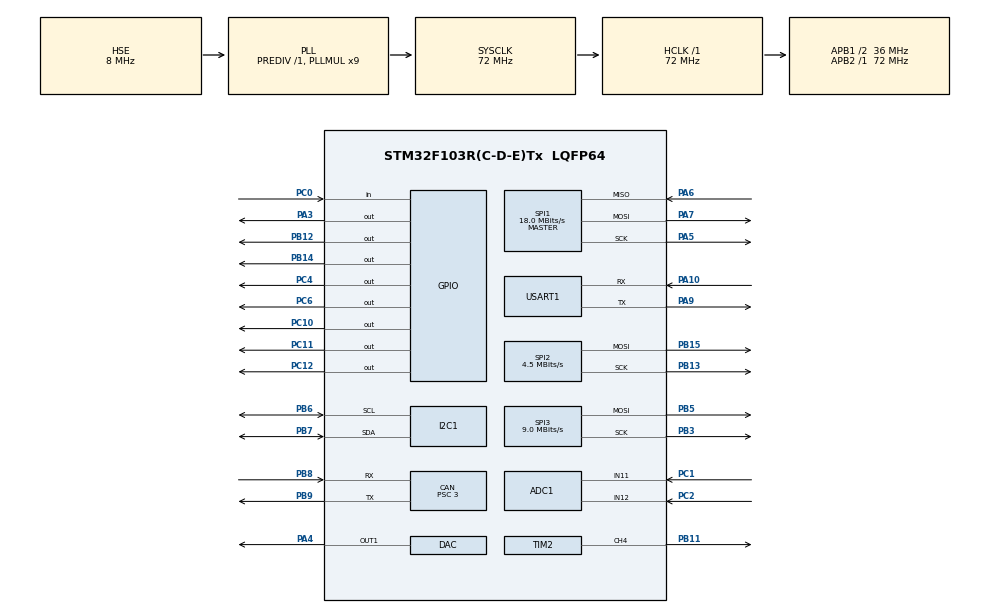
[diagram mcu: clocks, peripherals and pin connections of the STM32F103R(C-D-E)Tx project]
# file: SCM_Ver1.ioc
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ADC1.Channel-0\#ChannelRegularConversion=ADC_CHANNEL_11
ADC1.NbrOfConversionFlag=1
ADC1.master=1
CAN.ABOM=ENABLE
CAN.BS1=CAN_BS1_5TQ
CAN.BS2=CAN_BS2_6TQ
CAN.CalculateTimeBit=1000
CAN.CalculateTimeQuantum=83.33333333333334
CAN.Mode=CAN_MODE_NORMAL
CAN.Prescaler=3
Dma.Request0=USART1_TX
Dma.Request1=USART1_RX
Dma.Request2=SPI3_TX
Dma.SPI3_TX.2.Direction=DMA_MEMORY_TO_PERIPH
Dma.SPI3_TX.2.Instance=DMA2_Channel2
Dma.SPI3_TX.2.MemDataAlignment=DMA_MDATAALIGN_BYTE
Dma.SPI3_TX.2.MemInc=DMA_MINC_ENABLE
Dma.SPI3_TX.2.Mode=DMA_NORMAL
Dma.SPI3_TX.2.PeriphDataAlignment=DMA_PDATAALIGN_BYTE
Dma.SPI3_TX.2.PeriphInc=DMA_PINC_DISABLE
Dma.SPI3_TX.2.Priority=DMA_PRIORITY_LOW
Dma.USART1_RX.1.Direction=DMA_PERIPH_TO_MEMORY
Dma.USART1_RX.1.Instance=DMA1_Channel5
Dma.USART1_RX.1.MemDataAlignment=DMA_MDATAALIGN_BYTE
Dma.USART1_RX.1.MemInc=DMA_MINC_ENABLE
Dma.USART1_RX.1.Mode=DMA_CIRCULAR
Dma.USART1_RX.1.PeriphDataAlignment=DMA_PDATAALIGN_BYTE
Dma.USART1_RX.1.PeriphInc=DMA_PINC_DISABLE
Dma.USART1_RX.1.Priority=DMA_PRIORITY_HIGH
Dma.USART1_TX.0.Direction=DMA_MEMORY_TO_PERIPH
Dma.USART1_TX.0.Instance=DMA1_Channel4
Dma.USART1_TX.0.MemDataAlignment=DMA_MDATAALIGN_BYTE
Dma.USART1_TX.0.MemInc=DMA_MINC_ENABLE
Dma.USART1_TX.0.Mode=DMA_NORMAL
Dma.USART1_TX.0.PeriphDataAlignment=DMA_PDATAALIGN_BYTE
Dma.USART1_TX.0.PeriphInc=DMA_PINC_DISABLE
Dma.USART1_TX.0.Priority=DMA_PRIORITY_HIGH
I2C1.I2C_Mode=I2C_Standard
Mcu.Family=STM32F1
Mcu.Name=STM32F103R(C-D-E)Tx
Mcu.Package=LQFP64
NVIC.DMA1_Channel4_IRQn=true\:0\:0\:false\:false\:true\:false\:true
NVIC.DMA1_Channel5_IRQn=true\:0\:0\:false\:false\:true\:false\:true
NVIC.DMA2_Channel2_IRQn=true\:0\:0\:false\:false\:true\:false\:true
NVIC.PriorityGroup=NVIC_PRIORITYGROUP_4
NVIC.TIM1_UP_IRQn=true\:0\:0\:false\:true\:true\:2\:true\:true
NVIC.USART1_IRQn=true\:1\:0\:true\:true\:true\:1\:true\:true
NVIC.USB_LP_CAN1_RX0_IRQn=true\:1\:0\:true\:false\:true\:true\:true
PA10.Mode=Asynchronous
PA10.Signal=USART1_RX
PA13.Mode=Serial_Wire
PA13.Signal=SYS_JTMS-SWDIO
PA14.Mode=Serial_Wire
PA14.Signal=SYS_JTCK-SWCLK
PA3.Signal=GPIO_Output
PA4.Signal=COMP_DAC1_group
PA5.Mode=Full_Duplex_Master
PA5.Signal=SPI1_SCK
PA6.Mode=Full_Duplex_Master
PA6.Signal=SPI1_MISO
PA7.Mode=Full_Duplex_Master
PA7.Signal=SPI1_MOSI
PA9.Mode=Asynchronous
PA9.Signal=USART1_TX
PB11.Signal=S_TIM2_CH4
PB12.Signal=GPIO_Output
PB13.Mode=TX_Only_Simplex_Unidirect_Master
PB13.Signal=SPI2_SCK
PB14.Signal=GPIO_Output
PB15.Mode=TX_Only_Simplex_Unidirect_Master
PB15.Signal=SPI2_MOSI
PB3.Mode=TX_Only_Simplex_Unidirect_Master
PB3.Signal=SPI3_SCK
PB5.Mode=TX_Only_Simplex_Unidirect_Master
PB5.Signal=SPI3_MOSI
PB6.Mode=I2C
PB6.Signal=I2C1_SCL
PB7.Mode=I2C
PB7.Signal=I2C1_SDA
PB8.Mode=Master
PB8.Signal=CAN_RX
PB9.Mode=Master
PB9.Signal=CAN_TX
PC0.Signal=GPIO_Input
PC1.Signal=ADCx_IN11
PC10.Signal=GPIO_Output
PC11.Signal=GPIO_Output
PC12.Signal=GPIO_Output
PC2.Signal=ADCx_IN12
PC4.Signal=GPIO_Output
PC6.Signal=GPIO_Output
PD0-OSC_IN.Mode=HSE-External-Oscillator
PD0-OSC_IN.Signal=RCC_OSC_IN
PD1-OSC_OUT.Mode=HSE-External-Oscillator
PD1-OSC_OUT.Signal=RCC_OSC_OUT
ProjectManager.HeapSize=0x200
ProjectManager.StackSize=0x400
ProjectManager.TargetToolchain=STM32CubeIDE
RCC.ADCPresc=RCC_ADCPCLK2_DIV6
RCC.AHBFreq_Value=72000000
RCC.APB1CLKDivider=RCC_HCLK_DIV2
RCC.APB1Freq_Value=36000000
RCC.APB1TimFreq_Value=72000000
RCC.APB2Freq_Value=72000000
RCC.APB2TimFreq_Value=72000000
RCC.HCLKFreq_Value=72000000
RCC.PLLMUL=RCC_PLL_MUL9
RCC.PLLSourceVirtual=RCC_PLLSOURCE_HSE
RCC.SYSCLKFreq_VALUE=72000000
RCC.SYSCLKSource=RCC_SYSCLKSOURCE_PLLCLK
RCC.USBFreq_Value=48000000
RCC.USBPrescaler=RCC_USBCLKSOURCE_PLL_DIV1_5
SH.ADCx_IN11.0=ADC1_IN11,IN11
SH.ADCx_IN12.0=ADC1_IN12,IN12
SH.COMP_DAC1_group.0=DAC_OUT1,DAC_OUT1
SH.S_TIM2_CH4.0=TIM2_CH4,PWM Generation4 CH4
SPI1.BaudRatePrescaler=SPI_BAUDRATEPRESCALER_4
SPI1.CalculateBaudRate=18.0 MBits/s
SPI1.Direction=SPI_DIRECTION_2LINES
SPI1.Mode=SPI_MODE_MASTER
SPI1.VirtualType=VM_MASTER
SPI2.BaudRatePrescaler=SPI_BAUDRATEPRESCALER_8
SPI2.CalculateBaudRate=4.5 MBits/s
SPI2.Direction=SPI_DIRECTION_2LINES
SPI2.Mode=SPI_MODE_MASTER
SPI2.VirtualType=VM_MASTER
SPI3.BaudRatePrescaler=SPI_BAUDRATEPRESCALER_4
SPI3.CalculateBaudRate=9.0 MBits/s
SPI3.Direction=SPI_DIRECTION_2LINES
SPI3.Mode=SPI_MODE_MASTER
SPI3.VirtualType=VM_MASTER
TIM1.Period=999
TIM1.Prescaler=71
TIM2.AutoReloadPreload=TIM_AUTORELOAD_PRELOAD_DISABLE
TIM2.Channel-PWM\ Generation4\ CH4=TIM_CHANNEL_4
TIM2.Period=1000-1
TIM2.Prescaler=72-1
TIM2.Pulse-PWM\ Generation4\ CH4=500
USART1.VirtualMode=VM_ASYNC
VP_CRC_VS_CRC.Mode=CRC_Activate
VP_TIM1_VS_ClockSourceINT.Mode=Internal
board=custom

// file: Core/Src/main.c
/* USER CODE BEGIN Header */
/**
  ******************************************************************************
  * @file           : main.c
  * @brief          : Main program body
  ******************************************************************************
  * @attention
  *
  * <h2><center>&copy; Copyright (c) 2019 STMicroelectronics.
  * All rights reserved.</center></h2>
  *
  * This software component is licensed by ST under BSD 3-Clause license,
  * the "License"; You may not use this file except in compliance with the
  * License. You may obtain a copy of the License at:
  *                        opensource.org/licenses/BSD-3-Clause
  *
  ******************************************************************************
  */
/* USER CODE END Header */

#include "main.h"
#include "adc.h"
#include "can.h"
#include "crc.h"
#include "dac.h"
#include "dma.h"
#include "i2c.h"
#include "spi.h"
#include "tim.h"
#include "usart.h"
#include "gpio.h"

/* USER CODE BEGIN Includes */
#include "CRC.h"
#include "SCM.h"
#include "ina226.h"
#include "ssd1306.h"
#include "upper.h"
/* USER CODE END Includes */

void SystemClock_Config(void);
static void MX_NVIC_Init(void);

int main(void)
{

  /* MCU Configuration--------------------------------------------------------*/

  /* Reset of all peripherals, Initializes the Flash interface and the Systick. */
  HAL_Init();

  /* Configure the system clock */
  SystemClock_Config();

  /* Initialize all configured peripherals */
  MX_GPIO_Init();
  MX_DMA_Init();
  MX_ADC1_Init();
  MX_CAN_Init();
  MX_DAC_Init();
  MX_I2C1_Init();
  MX_SPI1_Init();
  MX_SPI2_Init();
  MX_SPI3_Init();
  MX_TIM2_Init();
  MX_USART1_UART_Init();
  MX_TIM1_Init();
  MX_CRC_Init();

  /* Initialize interrupts */
  MX_NVIC_Init();
  /* USER CODE BEGIN 2 */

	  HAL_TIM_PWM_Start(&htim2,TIM_CHANNEL_4); //Breath light
	  HAL_DAC_Start(&hdac,DAC_CHANNEL_1);
	  HAL_CAN_MspInit(&hcan);
	  //Enable UART IDLE interrupt and set DMA for Unfixed-length Data Receiving
	  SCM_Init();
	  Ina226_Init();
	  ssd1306_Init();
	  UART_InitForUpper(&huart1);
	  MPU9255_Init();
	  //Start Tim1 for control task interrupt
	  HAL_TIM_Base_Start_IT(&htim1);
  /* USER CODE END 2 */

  /* Infinite loop */
   while (1)
  {

  }
}

void SystemClock_Config(void)
{
  RCC_OscInitTypeDef RCC_OscInitStruct = {0};
  RCC_ClkInitTypeDef RCC_ClkInitStruct = {0};
  RCC_PeriphCLKInitTypeDef PeriphClkInit = {0};

  /** Initializes the CPU, AHB and APB busses clocks
  */
  RCC_OscInitStruct.OscillatorType = RCC_OSCILLATORTYPE_HSE;
  RCC_OscInitStruct.HSEState = RCC_HSE_ON;
  RCC_OscInitStruct.HSEPredivValue = RCC_HSE_PREDIV_DIV1;
  RCC_OscInitStruct.HSIState = RCC_HSI_ON;
  RCC_OscInitStruct.PLL.PLLState = RCC_PLL_ON;
  RCC_OscInitStruct.PLL.PLLSource = RCC_PLLSOURCE_HSE;
  RCC_OscInitStruct.PLL.PLLMUL = RCC_PLL_MUL9;
  if (HAL_RCC_OscConfig(&RCC_OscInitStruct) != HAL_OK)
  {
    Error_Handler();
  }
  /** Initializes the CPU, AHB and APB busses clocks
  */
  RCC_ClkInitStruct.ClockType = RCC_CLOCKTYPE_HCLK|RCC_CLOCKTYPE_SYSCLK
                              |RCC_CLOCKTYPE_PCLK1|RCC_CLOCKTYPE_PCLK2;
  RCC_ClkInitStruct.SYSCLKSource = RCC_SYSCLKSOURCE_PLLCLK;
  RCC_ClkInitStruct.AHBCLKDivider = RCC_SYSCLK_DIV1;
  RCC_ClkInitStruct.APB1CLKDivider = RCC_HCLK_DIV2;
  RCC_ClkInitStruct.APB2CLKDivider = RCC_HCLK_DIV1;

  if (HAL_RCC_ClockConfig(&RCC_ClkInitStruct, FLASH_LATENCY_2) != HAL_OK)
  {
    Error_Handler();
  }
  PeriphClkInit.PeriphClockSelection = RCC_PERIPHCLK_ADC;
  PeriphClkInit.AdcClockSelection = RCC_ADCPCLK2_DIV6;
  if (HAL_RCCEx_PeriphCLKConfig(&PeriphClkInit) != HAL_OK)
  {
    Error_Handler();
  }
}

/**
  * @brief NVIC Configuration.
  * @retval None
  */
static void MX_NVIC_Init(void)
{
  /* USART1_IRQn interrupt configuration */
  HAL_NVIC_SetPriority(USART1_IRQn, 1, 0);
  HAL_NVIC_EnableIRQ(USART1_IRQn);
  /* TIM1_UP_IRQn interrupt configuration */
  HAL_NVIC_SetPriority(TIM1_UP_IRQn, 0, 0);
  HAL_NVIC_EnableIRQ(TIM1_UP_IRQn);
}

void Error_Handler(void)
{
}

/************************ (C) COPYRIGHT STMicroelectronics *****END OF FILE****/
